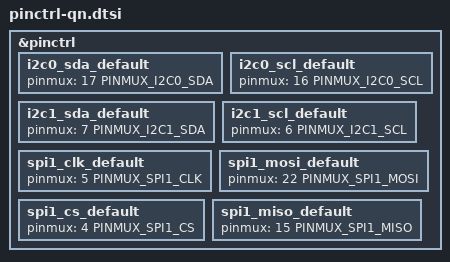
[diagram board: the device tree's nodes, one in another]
/*
 * Copyright (c) 2024-2026 Atmosic
 *
 * SPDX-License-Identifier: LicenseRef-Atmosic
 */

#include <atm34_pinmux.h>

&pinctrl {
	i2c0_sda_default: i2c0_sda_default {
		pinmux = <17 PINMUX_I2C0_SDA>;
	};

	i2c0_scl_default: i2c0_scl_default {
		pinmux = <16 PINMUX_I2C0_SCL>;
	};

	i2c1_sda_default: i2c1_sda_default {
		pinmux = <7 PINMUX_I2C1_SDA>;
	};

	i2c1_scl_default: i2c1_scl_default {
		pinmux = <6 PINMUX_I2C1_SCL>;
	};

	/* SPI1 */
	spi1_clk_default: spi1_clk_default {
		pinmux = <5 PINMUX_SPI1_CLK>;
	};

	spi1_mosi_default: spi1_mosi_default {
		pinmux = <22 PINMUX_SPI1_MOSI>;
	};

	spi1_cs_default: spi1_cs_default {
		pinmux = <4 PINMUX_SPI1_CS>;
	};

	spi1_miso_default: spi1_miso_default {
		pinmux = <15 PINMUX_SPI1_MISO>;
	};
};
